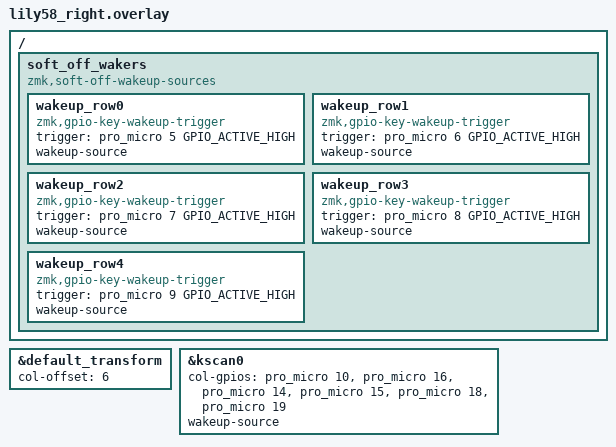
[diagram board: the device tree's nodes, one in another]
/*
 * Copyright (c) 2020 Pete Johanson
 *
 * SPDX-License-Identifier: MIT
 */

#include "lily58.dtsi"

&default_transform {
    col-offset = <6>;
};

&kscan0 {
    col-gpios
        = <&pro_micro 10 GPIO_ACTIVE_HIGH>
        , <&pro_micro 16 GPIO_ACTIVE_HIGH>
        , <&pro_micro 14 GPIO_ACTIVE_HIGH>
        , <&pro_micro 15 GPIO_ACTIVE_HIGH>
        , <&pro_micro 18 GPIO_ACTIVE_HIGH>
        , <&pro_micro 19 GPIO_ACTIVE_HIGH>
        ;
    wakeup-source;  // Thêm dòng này

};




/ {
    soft_off_wakers {
        compatible = "zmk,soft-off-wakeup-sources";
        status = "okay";
        
        wakeup_row0: wakeup_row0 {
            compatible = "zmk,gpio-key-wakeup-trigger";
            trigger = <&pro_micro 5 GPIO_ACTIVE_HIGH>;
            wakeup-source;
        };
        
        wakeup_row1: wakeup_row1 {
            compatible = "zmk,gpio-key-wakeup-trigger";
            trigger = <&pro_micro 6 GPIO_ACTIVE_HIGH>;
            wakeup-source;
        };
        
        wakeup_row2: wakeup_row2 {
            compatible = "zmk,gpio-key-wakeup-trigger";
            trigger = <&pro_micro 7 GPIO_ACTIVE_HIGH>;
            wakeup-source;
        };
        
        wakeup_row3: wakeup_row3 {
            compatible = "zmk,gpio-key-wakeup-trigger";
            trigger = <&pro_micro 8 GPIO_ACTIVE_HIGH>;
            wakeup-source;
        };
        
        wakeup_row4: wakeup_row4 {
            compatible = "zmk,gpio-key-wakeup-trigger";
            trigger = <&pro_micro 9 GPIO_ACTIVE_HIGH>;
            wakeup-source;
        };
    };
};
